VERSION ""

NS_ :

BS_:

BU_: XXX

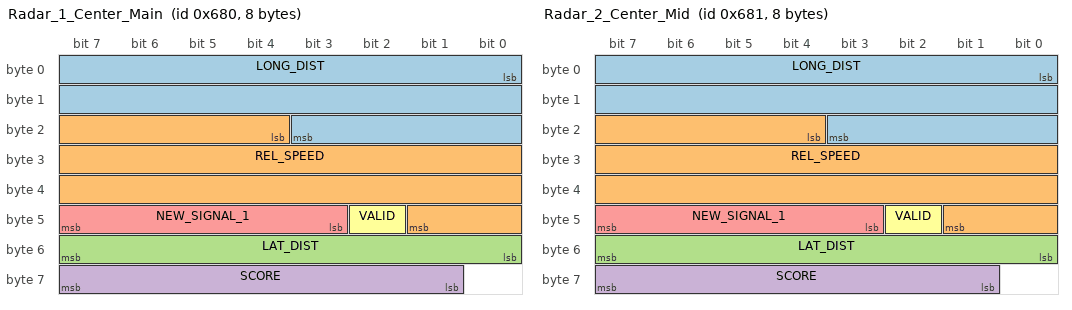
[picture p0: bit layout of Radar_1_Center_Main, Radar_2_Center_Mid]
BO_ 1664 Radar_1_Center_Main: 8 XXX
 SG_ LONG_DIST : 0|20@1+ (1,0) [0|127] "" XXX
 SG_ REL_SPEED : 20|22@1+ (1,0) [0|65535] "" XXX
 SG_ LAT_DIST : 48|8@1+ (1,-128) [0|3] "" XXX
 SG_ SCORE : 57|7@1+ (1,0) [0|3] "" XXX
 SG_ NEW_SIGNAL_1 : 47|5@0+ (1,0) [0|63] "" XXX
 SG_ VALID : 42|1@1+ (1,0) [0|3] "" XXX

BO_ 1665 Radar_2_Center_Mid: 8 XXX
 SG_ LONG_DIST : 0|20@1+ (1,0) [0|127] "" XXX
 SG_ REL_SPEED : 20|22@1+ (1,0) [0|65535] "" XXX
 SG_ LAT_DIST : 48|8@1+ (1,-128) [0|3] "" XXX
 SG_ SCORE : 57|7@1+ (1,0) [0|3] "" XXX
 SG_ NEW_SIGNAL_1 : 47|5@0+ (1,0) [0|63] "" XXX
 SG_ VALID : 42|1@1+ (1,0) [0|3] "" XXX

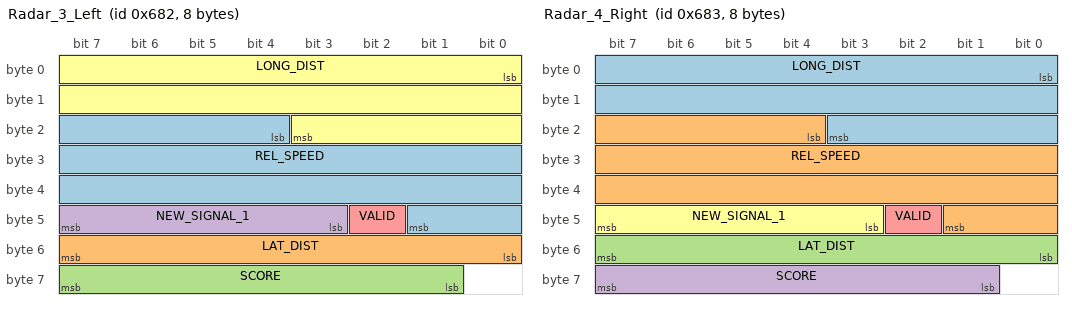
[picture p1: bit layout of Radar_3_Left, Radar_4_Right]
BO_ 1666 Radar_3_Left: 8 XXX
 SG_ REL_SPEED : 20|22@1+ (1,0) [0|65535] "" XXX
 SG_ LAT_DIST : 48|8@1+ (1,-128) [0|3] "" XXX
 SG_ SCORE : 57|7@1+ (1,0) [0|3] "" XXX
 SG_ NEW_SIGNAL_1 : 47|5@0+ (1,0) [0|63] "" XXX
 SG_ VALID : 42|1@1+ (1,0) [0|3] "" XXX
 SG_ LONG_DIST : 0|20@1+ (1,0) [0|127] "" XXX

BO_ 1667 Radar_4_Right: 8 XXX
 SG_ LONG_DIST : 0|20@1+ (1,0) [0|127] "" XXX
 SG_ REL_SPEED : 20|22@1+ (1,0) [0|65535] "" XXX
 SG_ LAT_DIST : 48|8@1+ (1,-128) [0|3] "" XXX
 SG_ SCORE : 57|7@1+ (1,0) [0|3] "" XXX
 SG_ VALID : 42|1@1+ (1,0) [0|3] "" XXX
 SG_ NEW_SIGNAL_1 : 47|5@0+ (1,0) [0|63] "" XXX

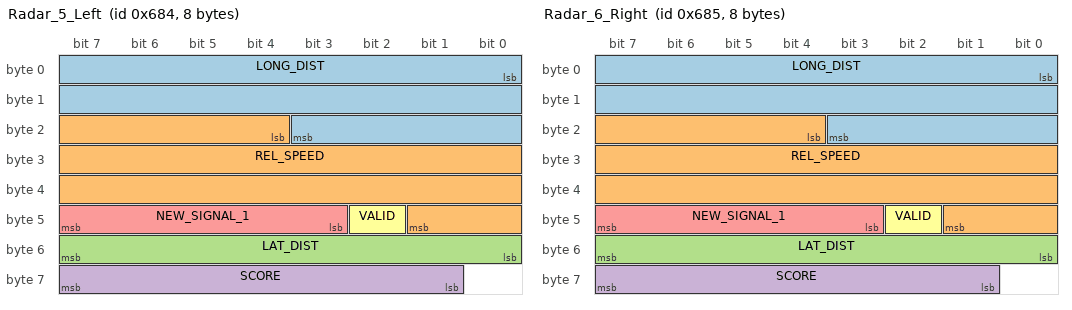
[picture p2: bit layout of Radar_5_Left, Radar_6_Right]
BO_ 1668 Radar_5_Left: 8 XXX
 SG_ LONG_DIST : 0|20@1+ (1,0) [0|127] "" XXX
 SG_ REL_SPEED : 20|22@1+ (1,0) [0|65535] "" XXX
 SG_ LAT_DIST : 48|8@1+ (1,-128) [0|3] "" XXX
 SG_ SCORE : 57|7@1+ (1,0) [0|3] "" XXX
 SG_ NEW_SIGNAL_1 : 47|5@0+ (1,0) [0|63] "" XXX
 SG_ VALID : 42|1@1+ (1,0) [0|3] "" XXX

BO_ 1669 Radar_6_Right: 8 XXX
 SG_ LONG_DIST : 0|20@1+ (1,0) [0|127] "" XXX
 SG_ REL_SPEED : 20|22@1+ (1,0) [0|65535] "" XXX
 SG_ LAT_DIST : 48|8@1+ (1,-128) [0|3] "" XXX
 SG_ SCORE : 57|7@1+ (1,0) [0|3] "" XXX
 SG_ NEW_SIGNAL_1 : 47|5@0+ (1,0) [0|63] "" XXX
 SG_ VALID : 42|1@1+ (1,0) [0|3] "" XXX

CM_ SG_ 1664 Tracking_Confidence "127 = confident, 87 = kinda confident, 0 = no tracking";
